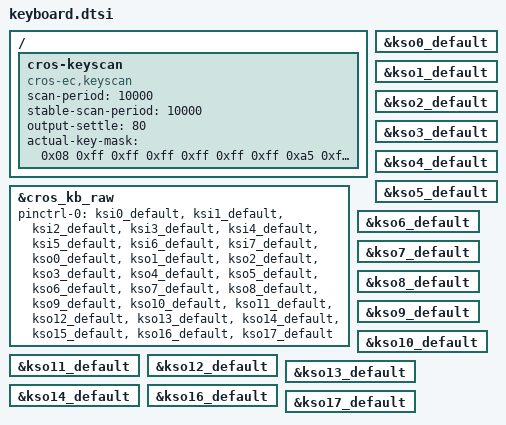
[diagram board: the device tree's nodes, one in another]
/* Copyright 2025 The ChromiumOS Authors
 * Use of this source code is governed by a BSD-style license that can be
 * found in the LICENSE file.
 */

/ {
	cros-keyscan {
		compatible = "cros-ec,keyscan";

		scan-period = <10000>;
		stable-scan-period = <10000>;
		output-settle = <80>; /* us */

		actual-key-mask = <
			0x08	/* C0 */
			0xff	/* C1 */
			0xff	/* C2 */
			0xff	/* C3 */
			0xff	/* C4 */
			0xff	/* C5 */
			0xff	/* C6 */
			0xa5	/* C7 */
			0xff	/* C8 */
			0xff	/* C9 */
			0x55	/* C10 */
			0xff	/* C11 */
			0xff	/* C12 */
			0x40	/* C13 */
			0x0a	/* C14 */
			0x40	/* C15 */
			0xff	/* C16 */
			0xff	/* C17 */
		>;
	};
};

&cros_kb_raw {
	status = "okay";
	pinctrl-0 = <
		&ksi0_default
		&ksi1_default
		&ksi2_default
		&ksi3_default
		&ksi4_default
		&ksi5_default
		&ksi6_default
		&ksi7_default
		&kso0_default
		&kso1_default
		&kso2_default
		&kso3_default
		&kso4_default
		&kso5_default
		&kso6_default
		&kso7_default
		&kso8_default
		&kso9_default
		&kso10_default
		&kso11_default
		&kso12_default
		&kso13_default
		&kso14_default
		&kso15_default
		&kso16_default
		&kso17_default
	>;
	pinctrl-names = "default";
};

&kso0_default {
	/delete-property/ bias-pull-up;
};

&kso1_default {
	/delete-property/ bias-pull-up;
};

&kso2_default {
	/delete-property/ bias-pull-up;
};

&kso3_default {
	/delete-property/ bias-pull-up;
};

&kso4_default {
	/delete-property/ bias-pull-up;
};

&kso5_default {
	/delete-property/ bias-pull-up;
};

&kso6_default {
	/delete-property/ bias-pull-up;
};

&kso7_default {
	/delete-property/ bias-pull-up;
};

&kso8_default {
	/delete-property/ bias-pull-up;
};

&kso9_default {
	/delete-property/ bias-pull-up;
};

&kso10_default {
	/delete-property/ bias-pull-up;
};

&kso11_default {
	/delete-property/ bias-pull-up;
};

&kso12_default {
	/delete-property/ bias-pull-up;
};

&kso13_default {
	/delete-property/ bias-pull-up;
};

&kso14_default {
	/delete-property/ bias-pull-up;
};

&kso16_default {
	/delete-property/ bias-pull-up;
};

&kso17_default {
	/delete-property/ bias-pull-up;
};
